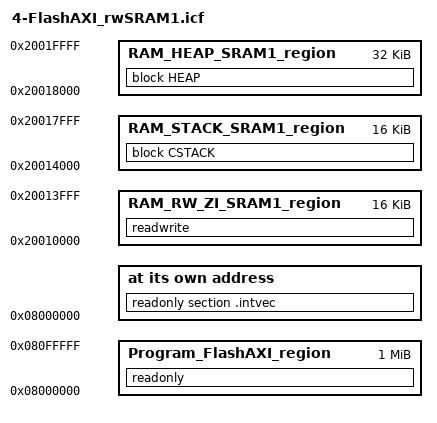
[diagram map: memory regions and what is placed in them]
/*###ICF### Section handled by ICF editor, don't touch! ****/
/*-Editor annotation file-*/
/* IcfEditorFile="$TOOLKIT_DIR$\config\ide\IcfEditor\cortex_v1_0.xml" */
/*-Specials-*/
define symbol __ICFEDIT_intvec_start__ = 0x08000000;

/*= Code region(s) ===================================== */
/* -- Program region in internal Flash ----------------- */
define symbol __ICFEDIT_Program_In_FlashAXI_start__    = 0x08000000;
define symbol __ICFEDIT_Program_In_FlashAXI_end__      = 0x080FFFFF;

/*= Data region(s) ===================================== */
/* RAM -- +RW +ZI region ------------------------------- */
/* The RW and Zero Initialized data will be located Internal SRAM1 (0x4000 = 16k) 
  All global variables will be located this section. */
define symbol __ICFEDIT_region_RW_ZI_SRAM1_start__  = 0x20010000;
define symbol __ICFEDIT_region_RW_ZI_SRAM1_end__    = 0x20013FFF;

/* RAM -- STACK region --------------------------------- */
/* The Stack of the main application will be located Internal SRAM1 (0x4000 = 16k)
 All internal variables of called functions will be located in this region. */
define symbol __ICFEDIT_region_STACK_SRAM1_start__  = 0x20014000;
define symbol __ICFEDIT_region_STACK_SRAM1_end__    = 0x20017FFF;

/* RAM -- HEAP region ---------------------------------- */
/* The Heap of the main application will be located Internal SRAM1 (0x8000 = 32k)
 All dynamic allocations data got by malloc, realloc, calloc... will located 
 in this region.*/
define symbol __ICFEDIT_region_HEAP_SRAM1_start__   = 0x20018000;
define symbol __ICFEDIT_region_HEAP_SRAM1_end__     = 0x2001FFFF;

/*= STACK and Heap Sizes =============================== */
define symbol __ICFEDIT_size_cstack__ = 0x4000;  /* 16k */
define symbol __ICFEDIT_size_heap__   = 0x8000;  /* 32k */
/**** End of ICF editor section. ###ICF###*/

/*= Memory regions definition ========================== */
define memory mem with size = 4G;
define region Program_FlashAXI_region  = mem:[from __ICFEDIT_Program_In_FlashAXI_start__   to __ICFEDIT_Program_In_FlashAXI_end__];
define region RAM_RW_ZI_SRAM1_region   = mem:[from __ICFEDIT_region_RW_ZI_SRAM1_start__ to __ICFEDIT_region_RW_ZI_SRAM1_end__];
define region RAM_STACK_SRAM1_region   = mem:[from __ICFEDIT_region_STACK_SRAM1_start__ to __ICFEDIT_region_STACK_SRAM1_end__];
define region RAM_HEAP_SRAM1_region    = mem:[from __ICFEDIT_region_HEAP_SRAM1_start__ to __ICFEDIT_region_HEAP_SRAM1_end__];


define block CSTACK    with alignment = 8, size = __ICFEDIT_size_cstack__   { };
define block HEAP      with alignment = 8, size = __ICFEDIT_size_heap__     { };

initialize by copy { readwrite }; 
                     
do not initialize  { section .noinit };

place at address mem:__ICFEDIT_intvec_start__ { readonly section .intvec };

place in Program_FlashAXI_region { readonly };

place in RAM_RW_ZI_SRAM1_region  { readwrite };
place in RAM_STACK_SRAM1_region  { block CSTACK };
place in RAM_HEAP_SRAM1_region   { block HEAP };

/*    SRAM1 partitioning:
              ____________________    __ 0x20010000  RW/ZI region TOP
             |               |    |
             |               |    |
             |    RW & ZI   \ /   |   -> 16k
             |               v    |
             |____________________|   __ 0x20014000
             |                    |
             |               ^    |   -> 16k
             |      Stack   / \   |
             |               |    |
             |_______________|____|   __ 0x20018000 (0x20014000+0x4000) STACK region TOP / Heap region TOP 
             |   |                | 
             |   |                | 
             |  \ /   Heap        |  -> 32k
             |   v                | 
             |____________________|   __ 0x20020000	

			 
*/		 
